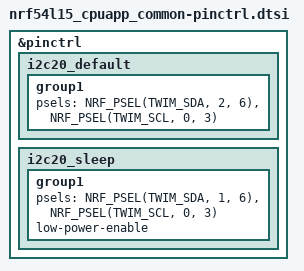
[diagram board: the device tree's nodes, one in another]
/*
 * Copyright (c) 2025 Daniel Kampert
 *
 * SPDX-License-Identifier: Apache-2.0
 */

&pinctrl {
    i2c20_default: i2c20_default {
        group1 {
            psels = <NRF_PSEL(TWIM_SDA, 2, 6)>,
                    <NRF_PSEL(TWIM_SCL, 0, 3)>;
        };
    };

    i2c20_sleep: i2c20_sleep {
        group1 {
            psels = <NRF_PSEL(TWIM_SDA, 1, 6)>,
                    <NRF_PSEL(TWIM_SCL, 0, 3)>;
            low-power-enable;
        };
    };
};
